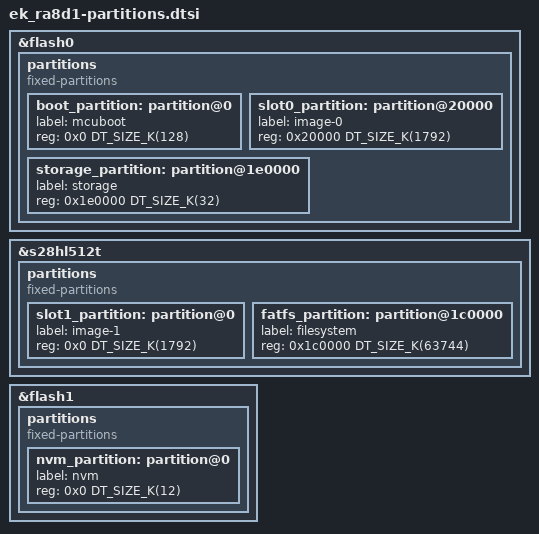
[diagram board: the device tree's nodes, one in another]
/* Partition layout for ek_ra8d1: the flash memory map shared by the
 * bootloader and every application image. Generated by
 * tools/partition_layout.py; do not edit by hand -- re-run
 * `python3 tools/partition_layout.py --fix ek_ra8d1` after changing
 * the upstream board geometry or tools/boards.toml.
 *
 * Board-specific overlay glue (delete-nodes, device enablement,
 * aliases/chosen) lives in dts/renesas/ek_ra8d1.dtsi, which includes
 * this file.
 */

&flash0 {
	partitions {
		compatible = "fixed-partitions";
		#address-cells = <1>;
		#size-cells = <1>;

		boot_partition: partition@0 {
			label = "mcuboot";
			reg = <0x0 DT_SIZE_K(128)>;
		};

		slot0_partition: partition@20000 {
			label = "image-0";
			reg = <0x20000 DT_SIZE_K(1792)>;
		};

		storage_partition: partition@1e0000 {
			label = "storage";
			reg = <0x1e0000 DT_SIZE_K(32)>;
		};
	};
};

&s28hl512t {
	partitions {
		compatible = "fixed-partitions";
		#address-cells = <1>;
		#size-cells = <1>;

		slot1_partition: partition@0 {
			label = "image-1";
			reg = <0x0 DT_SIZE_K(1792)>;
		};

		fatfs_partition: partition@1c0000 {
			label = "filesystem";
			reg = <0x1c0000 DT_SIZE_K(63744)>;
		};
	};
};

&flash1 {
	partitions {
		compatible = "fixed-partitions";
		#address-cells = <1>;
		#size-cells = <1>;

		nvm_partition: partition@0 {
			label = "nvm";
			reg = <0x0 DT_SIZE_K(12)>;
		};
	};
};
